# STM32F303C6T6 register map
File version: 1.0
Registers are 32-bit, access not given, reset 0x0 unless marked. A register's access mark holds for its fields unless they carry their own. Offsets are from the block's base; [hi:lo] are bit positions; {n}, {i} and the like mark numbered series.

## PWR
Base 0x40007000
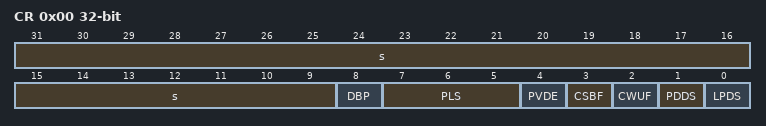
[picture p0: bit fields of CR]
0x00 CR
  [31:9] s, [8] DBP, [7:5] PLS, [4] PVDE, [3] CSBF, [2] CWUF, [1] PDDS, [0] LPDS
0x04 CSR
  [10] EWUP3, [9] EWUP2, [8] EWUP1, [31:4] s, [3] VREFINTRDYF, [2] PVDO, [1] SBF, [0] WUF

## DAC1
Base 0x40007400
Same registers: DAC2 0x40009800
0x00 CR
  [29] DMAUDRIE2, [28] DMAEN2, [27:24] MAMP2, [23:22] WAVE2, [21:19] TSEL2, [18] TEN2, [17] BOFF2, [16] EN2, [31:14] s, [13] DMAUDRIE1, [12] DMAEN1, [11:8] MAMP1, [7:6] WAVE1, [5:3] TSEL1, [2] TEN1, [1] BOFF1, [0] EN1
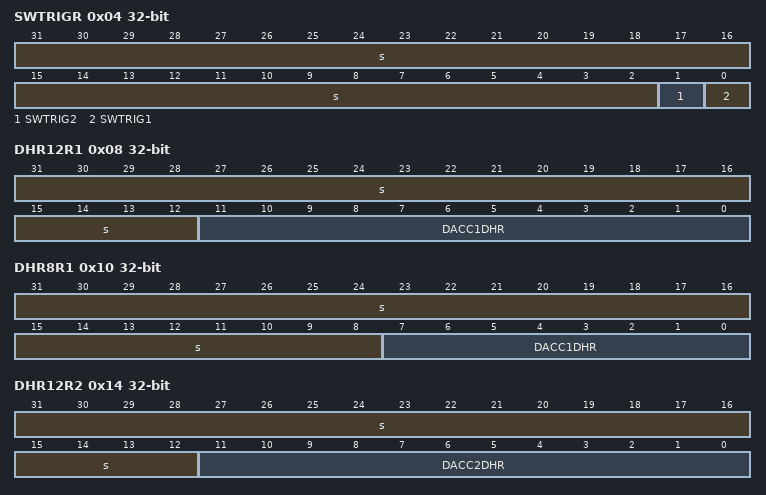
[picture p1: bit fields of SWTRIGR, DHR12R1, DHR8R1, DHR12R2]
0x04 SWTRIGR
  [31:2] s, [1] SWTRIG2, [0] SWTRIG1
0x08 DHR12R1
  [31:12] s, [11:0] DACC1DHR
0x0C DHR12L1
  [15:4] DACC1DHR, [31:0] s
0x10 DHR8R1
  [31:8] s, [7:0] DACC1DHR
0x14 DHR12R2
  [31:12] s, [11:0] DACC2DHR
0x18 DHR12L2
  [15:4] DACC2DHR, [31:0] s
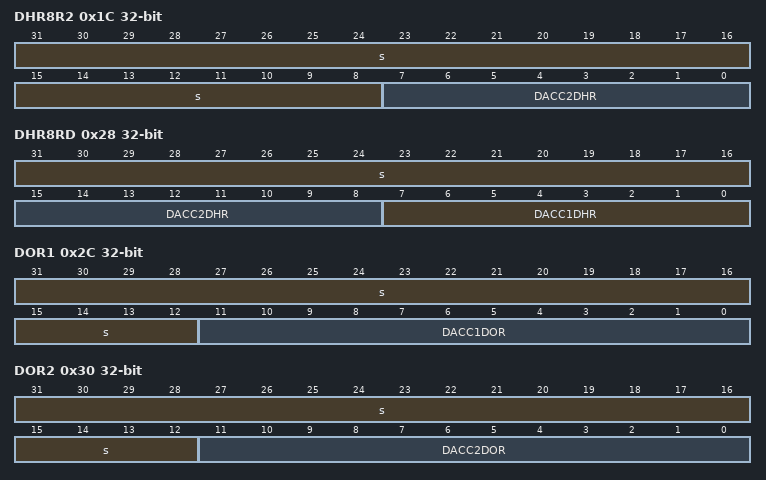
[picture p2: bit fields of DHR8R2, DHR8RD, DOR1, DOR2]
0x1C DHR8R2
  [31:8] s, [7:0] DACC2DHR
0x20 DHR12RD
  [27:16] DACC2DHR, [31:12] s, [11:0] DACC1DHR
0x24 DHR12LD
  [31:20] DACC2DHR, [15:4] DACC1DHR, [19:0] s
0x28 DHR8RD
  [31:16] s, [15:8] DACC2DHR, [7:0] DACC1DHR
0x2C DOR1
  [31:12] s, [11:0] DACC1DOR
0x30 DOR2
  [31:12] s, [11:0] DACC2DOR
0x34 SR
  [29] DMAUDR2, [13] DMAUDR1, [31:0] s

## COMP
Base 0x40010000
0x1C COMP1_CSR
  [31] COMP1LOCK, [30] COMP1OUT, [20:18] COMPx_BLANKING, [17:16] COMP1HYST, [15] COMP1POL, [13:10] COMP1OUTSEL, [29:7] s, [6:4] COMP1INSEL, [3:2] COMP1MODE, [1] COMP1_INP_DAC, [0] COMP1EN
0x20 COMP2_CSR
  [31] COMP2LOCK, [30] COMP2OUT, [20:18] COMP2_BLANKING, [15] COMP2POL, [13:10] COMP2OUTSEL, [9] COMP2WINMODE, [29:8] s, [7] COMP2INSEL, [22:4] COMP2INMSEL, [3:2] COMP2MODE, [1] COMP2_INP_DAC, [0] COMP2EN
0x24 COMP3_CSR
  [31] COMP3LOCK, [30] COMP3OUT, [20:18] COMP3_BLANKING, [17:16] COMP3HYST, [15] COMP3POL, [13:10] COMP3OUTSEL, [7] COMP3INSEL, [6:4] COMP3INMSEL, [3:2] COMP3MODE, [29:1] s, [0] COMP3EN
0x28 COMP4_CSR
  [31] COMP4LOCK, [30] COMP4OUT, [20:18] COMP4_BLANKING, [15] COMP4POL, [13:10] COMP4OUTSEL, [9] COMP4WINMODE, [7] COMP4INSEL, [22:4] COMP4INMSEL, [3:2] COMP4MODE, [29:1] s, [0] COMP4EN
0x2C COMP5_CSR
  [31] COMP5LOCK, [30] COMP5OUT, [20:18] COMP5_BLANKING, [17:16] COMP5HYST, [15] COMP5POL, [13:10] COMP5OUTSEL, [7] COMP5INSEL, [6:4] COMP5INMSEL, [3:2] COMP5MODE, [29:1] s, [0] COMP5EN
0x30 COMP6_CSR
  [31] COMP6LOCK, [30] COMP6OUT, [20:18] COMP6_BLANKING, [15] COMP6POL, [13:10] COMP6OUTSEL, [9] COMP6WINMODE, [7] COMP6INSEL, [22:4] COMP6INMSEL, [3:2] COMP6MODE, [29:1] s, [0] COMP6EN
0x34 COMP7_CSR
  [31] COMP7LOCK, [30] COMP7OUT, [20:18] COMP7_BLANKING, [17:16] COMP7HYST, [15] COMP7POL, [13:10] COMP7OUTSEL, [7] COMP7INSEL, [6:4] COMP7INMSEL, [3:2] COMP7MODE, [29:1] s, [0] COMP7EN

## OPAMP
Base 0x40010000
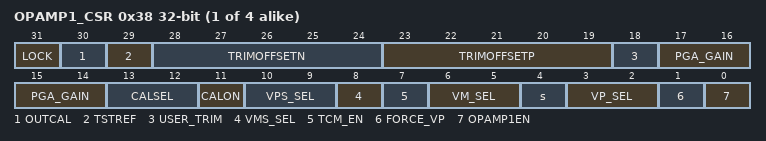
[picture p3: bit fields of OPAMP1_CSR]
{0x34+4i} OPAMP{i}_CSR (i=1..4)
  [31] LOCK, [30] OUTCAL, [29] TSTREF, [28:24] TRIMOFFSETN, [23:19] TRIMOFFSETP, [18] USER_TRIM, [17:14] PGA_GAIN, [13:12] CALSEL, [11] CALON, [10:9] VPS_SEL, [8] VMS_SEL, [7] TCM_EN, [6:5] VM_SEL, [4] s, [3:2] VP_SEL, [1] FORCE_VP, [0] OPAMP{i}EN

## SYSCFG
Base 0x40010000
0x00 CFGR1
  [31:26] FPU_IE, [23:22] ENCODER_MODE, [21] I2C2FMP, [20] _I2C1_FMP, [19] I2C_PB9_FMP, [18] I2C_PB8_FMP, [17] I2C_PB7_FMP, [16] I2CPB6FMP, [15] DAC2_CH1_DMA_RMP, [14] TIM7_DAC2_DMA_RMP, [13] TIM6_DAC1_DMA_RMP, [12] TIM17_DMA_RMP, [11] TIM16_DMA_RMP, [8] ADC24_DMA_RMP, [7] DAC_TRIG_RMP, [6] TIM1_ITR3_RMP, [5] USB_IT_RMP, [25:2] s, [1:0] MEM_MODE
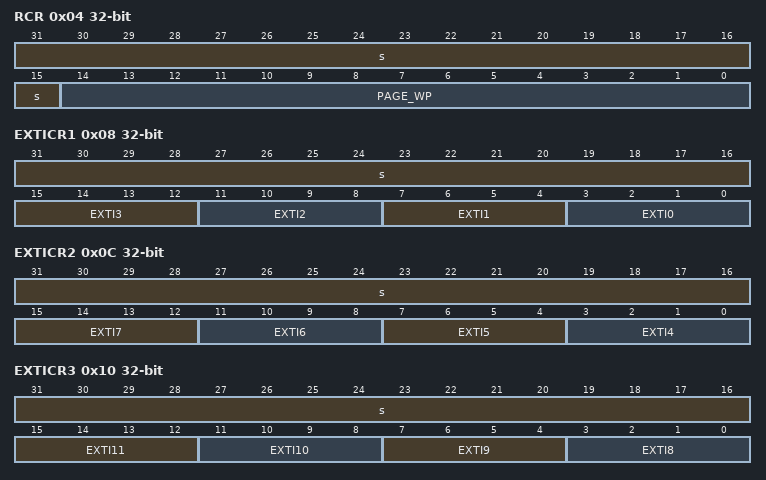
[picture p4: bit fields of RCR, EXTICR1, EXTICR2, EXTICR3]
0x04 RCR
  [31:15] s, [14:0] PAGE_WP
0x08 EXTICR1
  [31:16] s, [4n+3:4n] EXTI{n} (n=0..3)
0x0C EXTICR2
  [31:16] s, [4n-13:4n-16] EXTI{n} (n=4..7)
0x10 EXTICR3
  [31:16] s, [4n-29:4n-32] EXTI{n} (n=8..11)
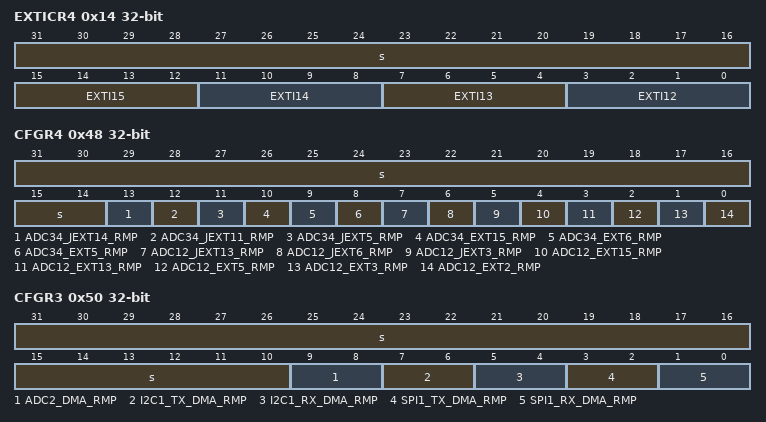
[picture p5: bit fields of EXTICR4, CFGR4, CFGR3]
0x14 EXTICR4
  [31:16] s, [4n-45:4n-48] EXTI{n} (n=12..15)
0x18 CFGR2
  [8] SRAM_PEF, [4] BYP_ADDR_PAR, [31:3] s, [2] PVD_LOCK, [1] SRAM_PARITY_LOCK, [0] LOCKUP_LOCK
0x48 CFGR4
  [31:14] s, [13] ADC34_JEXT14_RMP, [12] ADC34_JEXT11_RMP, [11] ADC34_JEXT5_RMP, [10] ADC34_EXT15_RMP, [9] ADC34_EXT6_RMP, [8] ADC34_EXT5_RMP, [7] ADC12_JEXT13_RMP, [6] ADC12_JEXT6_RMP, [5] ADC12_JEXT3_RMP, [4] ADC12_EXT15_RMP, [3] ADC12_EXT13_RMP, [2] ADC12_EXT5_RMP, [1] ADC12_EXT3_RMP, [0] ADC12_EXT2_RMP
0x50 CFGR3
  [31:10] s, [9:8] ADC2_DMA_RMP, [7:6] I2C1_TX_DMA_RMP, [5:4] I2C1_RX_DMA_RMP, [3:2] SPI1_TX_DMA_RMP, [1:0] SPI1_RX_DMA_RMP
